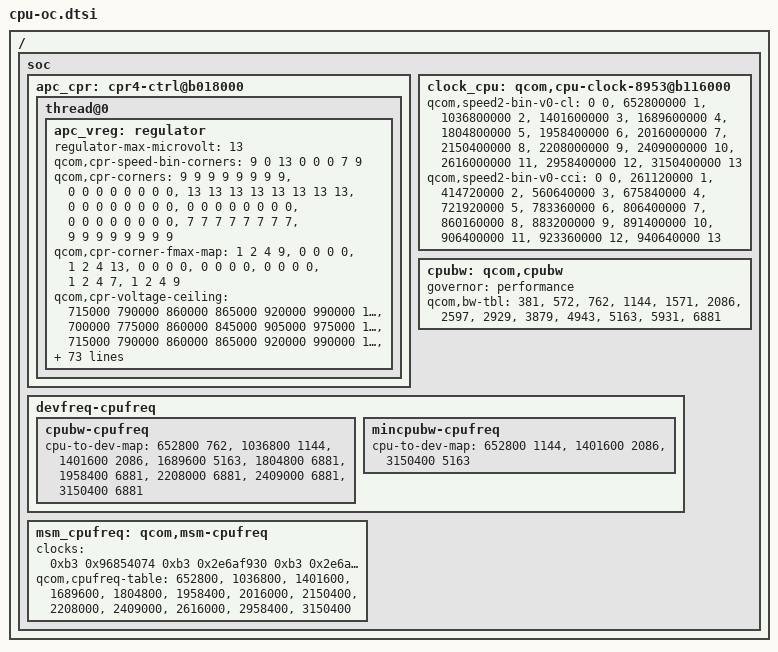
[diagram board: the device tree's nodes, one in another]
/*
 * Copyright (c) 2017, The Linux Foundation. All rights reserved.
 *
 * This program is free software; you can redistribute it and/or modify
 * it under the terms of the GNU General Public License version 2 and
 * only version 2 as published by the Free Software Foundation.
 *
 * This program is distributed in the hope that it will be useful,
 * but WITHOUT ANY WARRANTY; without even the implied warranty of
 * MERCHANTABILITY or FITNESS FOR A PARTICULAR PURPOSE.  See the
 * GNU General Public License for more details.
 */

/ {	
	soc {
		apc_cpr: cpr4-ctrl@b018000 {
			thread@0 {
				apc_vreg: regulator {
					regulator-max-microvolt = <13>;
					qcom,cpr-speed-bin-corners =
						<9 0 13 0 0 0 7 9>;
					qcom,cpr-corners =
						/* Speed bin 0 */
						<9 9 9 9 9 9 9 9>,
	
						/* Speed bin 1 */
						<0 0 0 0 0 0 0 0>,
	
						/* Speed bin 2 */
						<13 13 13 13 13 13 13 13>,
	
						/* Speed bin 3..5 */
						<0 0 0 0 0 0 0 0>,
						<0 0 0 0 0 0 0 0>,
						<0 0 0 0 0 0 0 0>,
	
						/* Speed bin 6 */
						<7 7 7 7 7 7 7 7>,
	
						/* Speed bin 7 */
						<9 9 9 9 9 9 9 9>;
	
					qcom,cpr-corner-fmax-map =
						/* Speed bin 0 */
						<1 2 4 9>,
	
						/* Speed bin 1 */
						<0 0 0 0>,
	
						/* Speed bin 2 */
						<1 2 4 13>,
	
						/* Speed bin 3..5 */
						<0 0 0 0>,
						<0 0 0 0>,
						<0 0 0 0>,
	
						/* Speed bin 6 */
						<1 2 4 7>,
	
						/* Speed bin 7 */
						<1 2 4 9>;
	
					qcom,cpr-voltage-ceiling =
						/* Speed bin 0 */
						<715000  790000 860000 865000 920000
						 990000 1065000 1065000 1065000>,
	
						/* Speed bin 2 */
						<700000  775000 860000 845000 905000
						 975000 1050000 1050000 1050000 1060000
						 1075000 1085000 1096000>,
	
						/* Speed bin 6 */
						<715000  790000 860000 865000 920000
						 990000 1065000>,
	
						/* Speed bin 7 */
						<715000  790000 860000 865000 920000
						 990000 1065000 1065000 1065000>;
	
					qcom,cpr-voltage-floor =
						/* Speed bin 0 */
						<500000  500000 500000 500000 500000
						 500000  500000 500000 500000>,
	
						/* Speed bin 2 */
						<500000  500000 500000 500000 500000
						 500000  500000 500000 500000 500000
						 500000  500000 500000>,
	
						/* Speed bin 6 */
						<500000  500000 500000 500000 500000
						 500000  500000>,
	
						/* Speed bin 7 */
						<500000  500000 500000 500000 500000
						 500000  500000 500000 500000>;
	
					qcom,cpr-floor-to-ceiling-max-range =
						/* Speed bin 0; CPR rev 0..7 */
						 <    0     0     0     0     0
						      0     0     0     0>,
						 <50000 50000 50000 50000 50000
						  50000 50000 50000 50000>,
						 <50000 50000 50000 50000 50000
						  50000 50000 50000 50000>,
						 <50000 50000 50000 50000 50000
						  50000 50000 50000 50000>,
						 <50000 50000 50000 50000 50000
						  50000 50000 50000 50000>,
						 <50000 50000 50000 50000 50000
						  50000 50000 50000 50000>,
						 <50000 50000 50000 50000 50000
						  50000 50000 50000 50000>,
						 <50000 50000 50000 50000 50000
						  50000 50000 50000 50000>,
	
						/* Speed bin 2; CPR rev 0..7 */
						 <    0     0     0     0     0
						      0     0     0     0     0
							  0     0     0>,
						 <50000 50000 50000 50000 50000
						  50000 50000 50000 50000 50000
						  50000 50000 50000>,
						 <50000 50000 50000 50000 50000
						  50000 50000 50000 50000 50000
						  50000 50000 50000>,
						 <50000 50000 50000 50000 50000
						  50000 50000 50000 50000 50000
						  50000 50000 50000>,
						 <50000 50000 50000 50000 50000
						  50000 50000 50000 50000 50000
						  50000 50000 50000>,
						 <50000 50000 50000 50000 50000
						  50000 50000 50000 50000 50000
						  50000 50000 50000>,
						 <50000 50000 50000 50000 50000
						  50000 50000 50000 50000 50000
						  50000 50000 50000>,
						 <50000 50000 50000 50000 50000
						  50000 50000 50000 50000 50000
						  50000 50000 50000>,
	
						/* Speed bin 6; CPR rev 0..7 */
						 <    0     0     0     0     0
						      0     0>,
						 <50000 50000 50000 50000 50000
						  50000 50000>,
						 <50000 50000 50000 50000 50000
						  50000 50000>,
						 <50000 50000 50000 50000 50000
						  50000 50000>,
						 <50000 50000 50000 50000 50000
						  50000 50000>,
						 <50000 50000 50000 50000 50000
						  50000 50000>,
						 <50000 50000 50000 50000 50000
						  50000 50000>,
						 <50000 50000 50000 50000 50000
						  50000 50000>,
	
						/* Speed bin 7; CPR rev 0..7 */
						 <    0     0     0     0     0
						      0     0     0     0>,
						 <50000 50000 50000 50000 50000
						  50000 50000 50000 50000>,
						 <50000 50000 50000 50000 50000
						  50000 50000 50000 50000>,
						 <50000 50000 50000 50000 50000
						  50000 50000 50000 50000>,
						 <50000 50000 50000 50000 50000
						  50000 50000 50000 50000>,
						 <50000 50000 50000 50000 50000
						  50000 50000 50000 50000>,
						 <50000 50000 50000 50000 50000
						  50000 50000 50000 50000>,
						 <50000 50000 50000 50000 50000
						  50000 50000 50000 50000>;
	
					qcom,cpr-misc-fuse-voltage-adjustment =
						/* Speed bin 0; misc fuse 0..1 */
						<    0     0     0     0      0
						     0     0     0     0>,
						<    0     0 30000     0      0
						     0     0     0     0>,
	
						/* Speed bin 2; misc fuse 0..1 */
						<    0     0     0     0      0
						     0     0     0     0      0
							 0     0     0>,
						<    0     0 30000     0      0
						     0     0     0     0      0
							 0     0     0>,
	
						/* Speed bin 6; misc fuse 0..1 */
						<    0     0     0     0      0
						     0     0>,
						<    0     0 30000     0      0
						     0     0>,
	
						/* Speed bin 7; misc fuse 0..1 */
						<    0     0     0     0      0
						     0     0     0     0>,
						<    0     0 30000     0      0
						     0     0     0     0>;
	
					qcom,mem-acc-voltage =
						/* Speed bin 0 */
						<1 1 2 2 2 2 2 2 2>,
	
						/* Speed bin 2 */
						<1 1 2 2 2 2 2 2 2 2 2 2 2>,
	
						/* Speed bin 6 */
						<1 1 2 2 2 2 2>,
	
						/* Speed bin 7 */
						<1 1 2 2 2 2 2 2 2>;
	
					qcom,corner-frequencies =
						/* Speed bin 0 */
						<652800000 1036800000 1401600000
						1689600000 1804800000 1958400000
						2016000000 2150400000 2208000000>,
	
						/* Speed bin 2 */
						<652800000 1036800000 1401600000
						1689600000 1804800000 1958400000
						2016000000 2150400000 2208000000
						2409000000 2616000000 2958400000
						3150400000>,
	
						/* Speed bin 6 */
						<652800000 1036800000 1401600000
						1689600000 1804800000 1958400000
						2016000000>,
	
						/* Speed bin 7 */
						<652800000 1036800000 1401600000
						1689600000 1804800000 1958400000
						2016000000 2150400000 2208000000>;
					qcom,corner-allow-temp-adjustment =
						/* Speed bin 0; CPR rev 0..7 */
						<0 0 0 0 0 0 0 0 0>,
						<0 0 0 0 0 0 0 0 0>,
						<0 0 0 0 0 0 0 0 0>,
						<1 1 1 1 0 0 0 0 0>,
						<1 1 1 1 0 0 0 0 0>,
						<1 1 1 1 0 0 0 0 0>,
						<1 1 1 1 0 0 0 0 0>,
						<1 1 1 1 0 0 0 0 0>,
	
						/* Speed bin 2; CPR rev 0..7 */
						<0 0 0 0 0 0 0 0 0 0 0 0 0>,
						<0 0 0 0 0 0 0 0 0 0 0 0 0>,
						<0 0 0 0 0 0 0 0 0 0 0 0 0>,
						<1 1 1 1 0 0 0 0 0 0 0 0 0>,
						<1 1 1 1 0 0 0 0 0 0 0 0 0>,
						<1 1 1 1 0 0 0 0 0 0 0 0 0>,
						<1 1 1 1 0 0 0 0 0 0 0 0 0>,
						<1 1 1 1 0 0 0 0 0 0 0 0 0>,
	
						/* Speed bin 6; CPR rev 0..7 */
						<0 0 0 0 0 0 0>,
						<0 0 0 0 0 0 0>,
						<0 0 0 0 0 0 0>,
						<1 1 1 1 0 0 0>,
						<1 1 1 1 0 0 0>,
						<1 1 1 1 0 0 0>,
						<1 1 1 1 0 0 0>,
						<1 1 1 1 0 0 0>,
	
						/* Speed bin 7; CPR rev 0..7 */
						<0 0 0 0 0 0 0 0 0>,
						<0 0 0 0 0 0 0 0 0>,
						<0 0 0 0 0 0 0 0 0>,
						<1 1 1 1 0 0 0 0 0>,
						<1 1 1 1 0 0 0 0 0>,
						<1 1 1 1 0 0 0 0 0>,
						<1 1 1 1 0 0 0 0 0>,
						<1 1 1 1 0 0 0 0 0>;
				};
			};
		};
		clock_cpu: qcom,cpu-clock-8953@b116000 {
			qcom,speed2-bin-v0-cl =
				<          0 0>,
				<  652800000 1>,
				< 1036800000 2>,
				< 1401600000 3>,
				< 1689600000 4>,
				< 1804800000 5>,
				< 1958400000 6>,
				< 2016000000 7>,
				< 2150400000 8>,
				< 2208000000 9>,
				< 2409000000 10>,
				< 2616000000 11>,
				< 2958400000 12>,
				< 3150400000 13>;
			qcom,speed2-bin-v0-cci =
				<          0 0>,
				<  261120000 1>,
				<  414720000 2>,
				<  560640000 3>,
				<  675840000 4>,
				<  721920000 5>,
				<  783360000 6>,
				<  806400000 7>,
				<  860160000 8>,
				<  883200000 9>,
				<  891400000 10>,
				<  906400000 11>,
				<  923360000 12>,
				< 940640000 13>;
		};
		cpubw: qcom,cpubw {
			governor = "performance";
			qcom,bw-tbl =
				<  381  /*  100 MHz */ >,
				<  572  /*  150 MHz */ >,
				<  762  /*  200 MHz */ >,
				<  1144 /*  300 MHz */ >,
				<  1571 /*  412 MHz */ >,
				<  2086 /*  547 MHz */ >,
				<  2597 /*  681 MHz */ >,
				<  2929 /*  768 MHz */ >,
				<  3879 /* 1017 MHz */ >,
				<  4943 /* 1296 MHz */ >,
				<  5163 /* 1353 MHz */ >,
				<  5931 /* 1555 MHz */ >,
				< 6881 /* 1804 MHz */ >;
		};
		devfreq-cpufreq {
			cpubw-cpufreq {
				cpu-to-dev-map =
					 <  652800  762 >,
					 < 1036800  1144>,
				 	 < 1401600  2086>,
				 	 < 1689600  5163>,
					 < 1804800  6881>,
					 < 1958400  6881>,
					 < 2208000  6881>,
					 < 2409000  6881>,
					 < 3150400  6881>;
			};
			mincpubw-cpufreq {
				cpu-to-dev-map =
					<  652800 1144 >,
					< 1401600 2086 >,
					< 3150400 5163 >;
			};
		};
		msm_cpufreq: qcom,msm-cpufreq {
			clock-names = "l2_clk", "cpu0_clk", "cpu1_clk", "cpu2_clk",
					"cpu3_clk", "cpu4_clk", "cpu5_clk",
					"cpu6_clk", "cpu7_clk", "cpu8_clk", "cpu9_clk",
					"cpu10_clk", "cpu11_clk", "cpu12_clk";
			clocks = < 0xb3 0x96854074 0xb3 0x2e6af930 0xb3 0x2e6af930 0xb3 0x2e6af930 0xb3 0x2e6af930 0xb3 0x2e6af930 0xb3 0x2e6af930 0xb3 0x2e6af930 0xb3 0x2e6af930 0xb3 0x2e6af930 0xb3 0x2e6af930 0xb3 0x2e6af930 0xb3 0x2e6af930 0xb3 0x2e6af930 >;
			qcom,cpufreq-table =
				 <  652800 >,
				 < 1036800 >,
				 < 1401600 >,
				 < 1689600 >,
				 < 1804800 >,
				 < 1958400 >,
				 < 2016000 >,
				 < 2150400 >,
				 < 2208000 >,
				 < 2409000 >,
				 < 2616000 >,
				 < 2958400 >,
				 < 3150400 >;
		};
	};
};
